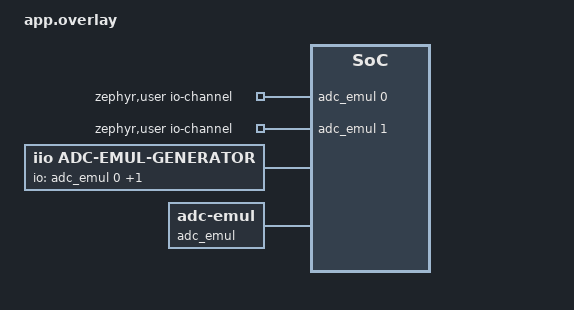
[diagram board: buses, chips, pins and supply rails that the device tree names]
/*
 * Copyright (c) 2026 Analog Devices, Inc.
 *
 * SPDX-License-Identifier: MIT
 */

/ {
	zephyr,user {
		io-channels = <&adc_emul 0>, <&adc_emul 1>;
	};

	generator {
		compatible = "iio,adc-emul-generator";
		io-channels = <&adc_emul 0>, <&adc_emul 1>;
	};

	adc_emul: adc {
		compatible = "zephyr,adc-emul";
		nchannels = <2>;
		ref-internal-mv = <3300>;
		#io-channel-cells = <1>;
		#address-cells = <1>;
		#size-cells = <0>;

		channel@0 {
			reg = <0>;
			zephyr,gain = "ADC_GAIN_1";
			zephyr,reference = "ADC_REF_INTERNAL";
			zephyr,acquisition-time = <ADC_ACQ_TIME_DEFAULT>;
			zephyr,resolution = <4>;
		};

		channel@1 {
			reg = <1>;
			zephyr,gain = "ADC_GAIN_1";
			zephyr,reference = "ADC_REF_INTERNAL";
			zephyr,acquisition-time = <ADC_ACQ_TIME_DEFAULT>;
			zephyr,resolution = <8>;
		};
	};
};
